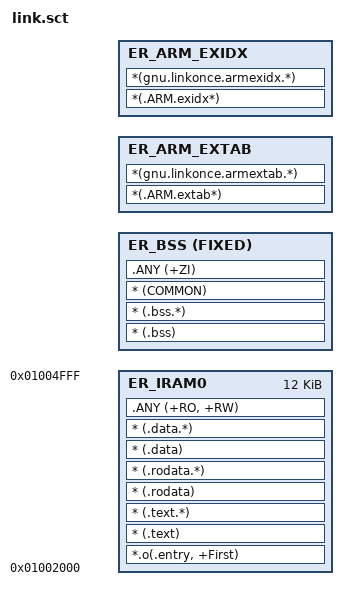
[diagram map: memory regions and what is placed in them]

; *************************************************************
; *** Scatter-Loading Description File generated by uVision ***
; *************************************************************

LR_IROM1 0x01002000 0x3000 { ; load region size_region
  ER_IRAM0 0x01002000 0x3000 { ; load address = execution address
    *.o(.entry, +First)
    * (.text)
    * (.text.*)
    * (.rodata)
    * (.rodata.*)
    * (.data)
    * (.data.*)
    .ANY (+RO, +RW)
  }
  ER_BSS +0 ALIGN 4 FIXED {
    * (.bss)
    * (.bss.*)
    * (COMMON)
    .ANY (+ZI)
  }

  ER_ARM_EXTAB +0 {
    *(.ARM.extab*)
    *(gnu.linkonce.armextab.*)
  }
  ER_ARM_EXIDX +0 {
    *(.ARM.exidx*)
    *(gnu.linkonce.armexidx.*)
  }
}
